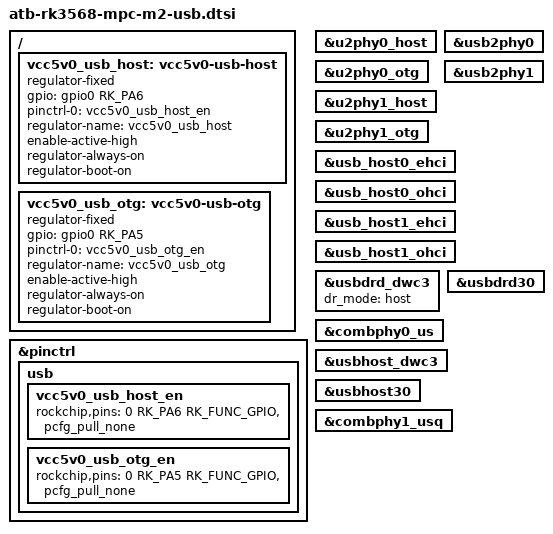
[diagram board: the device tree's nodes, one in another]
/{
	vcc5v0_usb_host: vcc5v0-usb-host {
		compatible = "regulator-fixed";
		gpio = <&gpio0 RK_PA6 GPIO_ACTIVE_HIGH>;
		pinctrl-names = "default";
		pinctrl-0 = <&vcc5v0_usb_host_en>;
		regulator-name = "vcc5v0_usb_host";
		enable-active-high;
		regulator-always-on;
		regulator-boot-on;

	};

	vcc5v0_usb_otg: vcc5v0-usb-otg {
		compatible = "regulator-fixed";
		gpio = <&gpio0 RK_PA5 GPIO_ACTIVE_HIGH>;
		pinctrl-names = "default";
		pinctrl-0 = <&vcc5v0_usb_otg_en>;
		regulator-name = "vcc5v0_usb_otg";
		enable-active-high;
		regulator-always-on;
		regulator-boot-on;

	};
};

&pinctrl {
	usb {
		vcc5v0_usb_host_en: vcc5v0_usb_host_en {
			rockchip,pins = <0 RK_PA6 RK_FUNC_GPIO &pcfg_pull_none>;
		};
		vcc5v0_usb_otg_en: vcc5v0_usb_otg_en {
			rockchip,pins = <0 RK_PA5 RK_FUNC_GPIO &pcfg_pull_none>;
		};
	};
};

&u2phy0_host {
	status = "okay";
};

&u2phy0_otg {
	status = "okay";
};

&u2phy1_host {
	status = "okay";
};

&u2phy1_otg {
	status = "okay";
};

&usb2phy0 {
	status = "okay";
};

&usb2phy1 {
	status = "okay";
};

&usb_host0_ehci {
	status = "okay";
};

&usb_host0_ohci {
	status = "okay";
};

&usb_host1_ehci {
	status = "okay";
};

&usb_host1_ohci {
	status = "okay";
};

&usbdrd_dwc3 {
	dr_mode = "host";
	status = "okay";
};

&usbdrd30 {
	status = "okay";
};

&combphy0_us {
	status = "okay";
};

&usbhost_dwc3 {
	status = "okay";
};

&usbhost30 {
	status = "okay";
};

&combphy1_usq {
	status = "okay";
};
